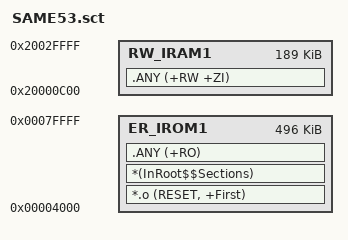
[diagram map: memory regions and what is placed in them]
; *************************************************************
; *** Scatter-Loading Description File generated by uVision ***
; *************************************************************

LR_IROM1 0x00004000 0x0007C000  {    ; load region size_region
  ER_IROM1 0x00004000 0x0007C000  {  ; load address = execution address
   *.o (RESET, +First)
   *(InRoot$$Sections)
   .ANY (+RO)
  }

  RW_IRAM1 0x20000C00 0x00002F400 {  ; RW data
   .ANY (+RW +ZI)
  }
}

